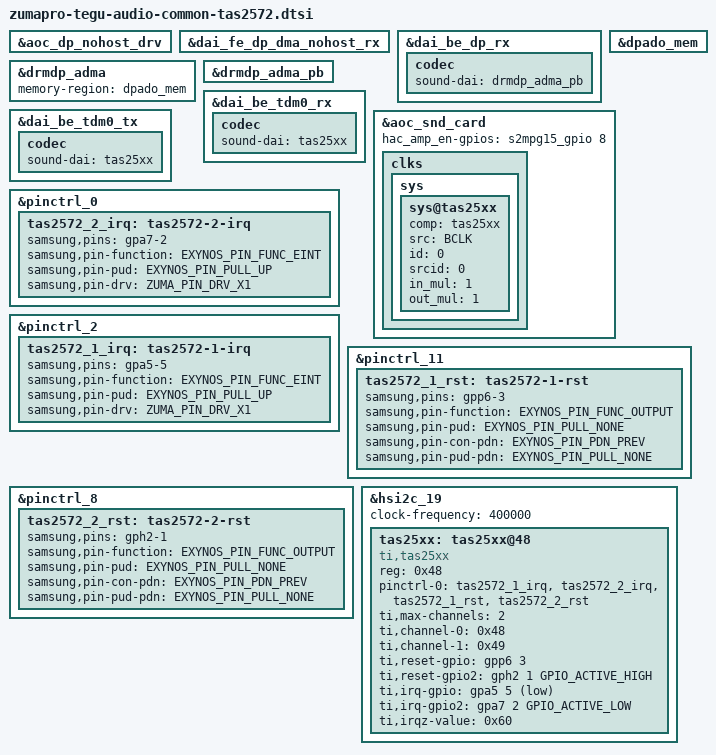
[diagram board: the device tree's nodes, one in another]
// SPDX-License-Identifier: GPL-2.0-only
/*
 * tegu common audio device tree source
 *
 * Copyright 2023 Google LLC
 */

#include <arm64/exynos/exynos-pinctrl.h>
#include <dt-bindings/interrupt-controller/irq.h>
#include <dt-bindings/gpio/gpio.h>
//#include <dt-bindings/sound/google-aoc.h>

/* DP audio */
&aoc_dp_nohost_drv {
	status = "okay";
};

/* DP audio */
&dai_fe_dp_dma_nohost_rx {
	status = "okay";
};

/* DP audio */
&dai_be_dp_rx {
	status = "okay";
	codec {
		sound-dai = <&drmdp_adma_pb>;
	};
};

/* DP audio */
&dpado_mem {
	status = "okay";
};

/* DP audio */
&drmdp_adma {
	status = "okay";
	memory-region = <&dpado_mem>;
};

/* DP audio */
&drmdp_adma_pb {
	status = "okay";
};

&dai_be_tdm0_rx {
	codec {
		sound-dai = <&tas25xx>;
	};
};

&dai_be_tdm0_tx {
	codec {
		sound-dai = <&tas25xx>;
	};
};

&aoc_snd_card {
	clks {
		sys {
			sys@tas25xx {
				comp = <&tas25xx>;
				src = "BCLK";
				/* clk id */
				id = <0>;
				/* clk source */
				srcid = <0>;
				/* in clk multiple */
				in_mul = <1>;
				/* out clk multiple */
				out_mul = <1>;
			};

		};
	};
};

/* GPIO_ALIVE */
&pinctrl_0 {
	tas2572_2_irq: tas2572-2-irq {
		samsung,pins = "gpa7-2"; /* XEINT_16 */
		samsung,pin-function = <EXYNOS_PIN_FUNC_EINT>;
		samsung,pin-pud = <EXYNOS_PIN_PULL_UP>;
		samsung,pin-drv = <ZUMA_PIN_DRV_X1>;
	};
};

/* GPIO_FAR_ALIVE */
&pinctrl_2 {
	tas2572_1_irq: tas2572-1-irq {
		samsung,pins = "gpa5-5"; /* XEINT_5 */
		samsung,pin-function = <EXYNOS_PIN_FUNC_EINT>;
		samsung,pin-pud = <EXYNOS_PIN_PULL_UP>;
		samsung,pin-drv = <ZUMA_PIN_DRV_X1>;
	};
};

/* GPIO_PERIC0 */
&pinctrl_11 {
	tas2572_1_rst: tas2572-1-rst {
		samsung,pins = "gpp6-3"; /* XAPC_USI3_CTSn_CSn */
		samsung,pin-function = <EXYNOS_PIN_FUNC_OUTPUT>;
		samsung,pin-pud = <EXYNOS_PIN_PULL_NONE>;
		samsung,pin-con-pdn = <EXYNOS_PIN_PDN_PREV>;
		samsung,pin-pud-pdn = <EXYNOS_PIN_PULL_NONE>;
	};
};

/* GPIO_PERIC1 */
&pinctrl_8 {
	tas2572_2_rst: tas2572-2-rst {
		samsung,pins = "gph2-1"; /* XHSI1_GPIO11 */
		samsung,pin-function = <EXYNOS_PIN_FUNC_OUTPUT>;
		samsung,pin-pud = <EXYNOS_PIN_PULL_NONE>;
		samsung,pin-con-pdn = <EXYNOS_PIN_PDN_PREV>;
		samsung,pin-pud-pdn = <EXYNOS_PIN_PULL_NONE>;
	};
};

&hsi2c_19 {
	#address-cells = <1>;
	#size-cells = <0>;

	status = "ok";
	clock-frequency = <400000>;

	tas25xx:tas25xx@48 {
		#sound-dai-cells = <0>;
		compatible = "ti,tas25xx";
		reg = <0x48>;

		pinctrl-names = "default";
		pinctrl-0 = <&tas2572_1_irq &tas2572_2_irq
				&tas2572_1_rst &tas2572_2_rst>;

		ti,max-channels = <2>;
		ti,channel-0 = <0x48>;
		ti,channel-1 = <0x49>;
		ti,reset-gpio = <&gpp6 3 GPIO_ACTIVE_HIGH>;
		ti,reset-gpio2 = <&gph2 1 GPIO_ACTIVE_HIGH>;
		ti,irq-gpio = <&gpa5 5 GPIO_ACTIVE_LOW>;
		ti,irq-gpio2 = <&gpa7 2 GPIO_ACTIVE_LOW>;
		ti,irqz-value = <0x60>;
		status = "ok";
	};
};

&aoc_snd_card {
	hac_amp_en-gpios = <&s2mpg15_gpio 8 GPIO_ACTIVE_HIGH>;
};

